# iND83213A register map
Vendor: Indiemicro; Series: Rugby; File version: 1.0
CPU: CM0 r0p1, selectable endian, no MPU, no FPU, 4 interrupt priority bits
Registers are 32-bit, read-write, no defined reset value unless marked. A register's access mark holds for its fields unless they carry their own. Offsets are from the block's base; [hi:lo] are bit positions; {n}, {i} and the like mark numbered series.

## SAR_CTRL — SAR ADC Interface registers
Base 0x50010600; register names take the prefix SAR_CTRL_
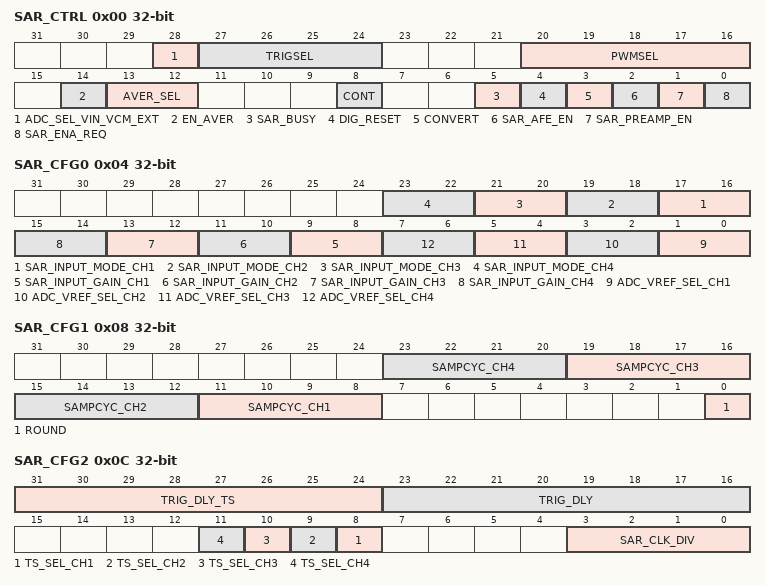
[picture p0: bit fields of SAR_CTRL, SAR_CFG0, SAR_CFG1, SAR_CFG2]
0x00 SAR_CTRL — SAR ADC Control
  [28] ADC_SEL_VIN_VCM_EXT — Select External Inputs to ADC. choose ADC input common voltage. 0: choose internal vin_vcm, equals to (vinp+vinn)/2; 1: choose external vin_vcm, for PN detect.
  [27:24] TRIGSEL — SAR Converion Trigger Selects. Selects the trigger condition of SAR ADC. Don't change the bits during an ADC conversion sequence is ongoing. 0x1: Triggered through writing 1 to conversion bit. 0x2: Triggered by the PWM posedge. 0x4: Triggered by the PWM negedge. 0x8: Triggered by PWM period.
  [20:16] PWMSEL — PWM Trigger Signal Selects. Selects the source PWM channel.
  [14] EN_AVER — Enable sample data average.
  [13:12] AVER_SEL — Select average numbers of adc sample data. 0x0: Average numbers of adc sample data: 4 0x1: Average numbers of adc sample data: 8 0x2: Average numbers of adc sample data: 16 0x3: Average numbers of adc sample data: 32
  [8] CONT — Continuous Conversion Enable. If this bit has been set before an ADC conversion sequence trigged by CONVERT bit, the sequence will be treated as a sequential conversion, rather than a single conversion, only value when auto_trg_en is disable.
  [5] SAR_BUSY ro — SAR ADC busy. When SAR ADC is running, the flag is set
  [4] DIG_RESET wo — SAR Digital Part Reset. Resets SAR digital parts. Autoclear: includes a synchronous reset signal which clears the register on the cycle following write.
  [3] CONVERT wo — ADC START Register. Set 1 to start a new adc conversion. NOTE: THAT BIT SHOULD NOT BE SET UNTIL ALL OTHER CONFIG BITS BE SETTED Autoclear: includes a synchronous reset signal which clears the register on the cycle following write.
  [2] SAR_AFE_EN — ADC AFE Enable. adc afe enable. If vinp, vinn and vin vcm all choose external, adc afe should be disabled: adc_adc_en=0, otherwise, adc afe must be enabled: adc_afe_en=1.
  [1] SAR_PREAMP_EN — adc pre-amp enable. 0:disable, 1:enable
  [0] SAR_ENA_REQ — SAR ADC Enable. Set to enable the SAR analog & digital part
0x04 SAR_CFG0 — SAR Configuration Register0
  [2n+15:2n+14] SAR_INPUT_MODE_CH{n} (n=1..4) — ADC AFE Input Modes for channel {n}. Select ADC AFE Input Modes. 0x0: All external. 0x1: VINP buffered, VINN external. 0x2: VINN buffered, VINP external. 0x3: Both VINP & VINN buffered.
  [2n+7:2n+6] SAR_INPUT_GAIN_CH{n} (n=1..4) — choose ADC input gain for channel {n}. 0x0: 14/32 0x1: 22/32 0x2: 31/32 0x3: 31/32
  [2n-1:2n-2] ADC_VREF_SEL_CH{n} (n=1..4) — adc vref select for channel {n}. 0x0: adc_vref = vbg when sar_ena_req=1 0x1: adc_vref = 2*vbg when sar_ena_req=1 0x2: adc_vref = VDD_3V3 when sar_ena_req=1 0x3: adc_vref = VDD_3V3 when sar_ena_req=1
0x08 SAR_CFG1 — SAR Configuration Register1
  [4n+7:4n+4] SAMPCYC_CH{n} (n=1..4) — Sample cycle for channel {n}. Set sampling time from 1 to 16 sar clock cycles. 0x0: 1 Cycle 0x1: 2 Cycle 0x2: 3 Cycle 0xf: 16 Cycle
  [0] ROUND — ADC round enable. Enable ADC round. 0x0: No round. 0x1: Negative code+1
0x0C SAR_CFG2 — SAR Configuration Register2
  [31:24] TRIG_DLY_TS — Trigger delay used for temp sensor sampling channel. Set trigger delay time from 1 to 256 sar clock cycles.
  [23:16] TRIG_DLY — Trigger delay used for non temp sensor sampling channel. Set trigger delay time from 1 to 256 sar clock cycles.
  [n+7] TS_SEL_CH{n} (n=1..4) — Temp sensor select for channel {n}. 1'b0: Temp sensor located in BUCK; 1'b1: Temp sensor located in LED. The value is only valid when Temp Sensor differential channel of CH{n} is selected.
  [3:0] SAR_CLK_DIV — SAR ADC reference clock div select. Select the divisor on the system clock after perscale. The sar adc clock = sysclk(16Mhz)/((CRGA.DIVSYSCLK+1)*(SAR_CLK_DIV+1)). The sar adc clock frequence must be no more than 4Mhz. The default sar adc clock: 1Mhz.
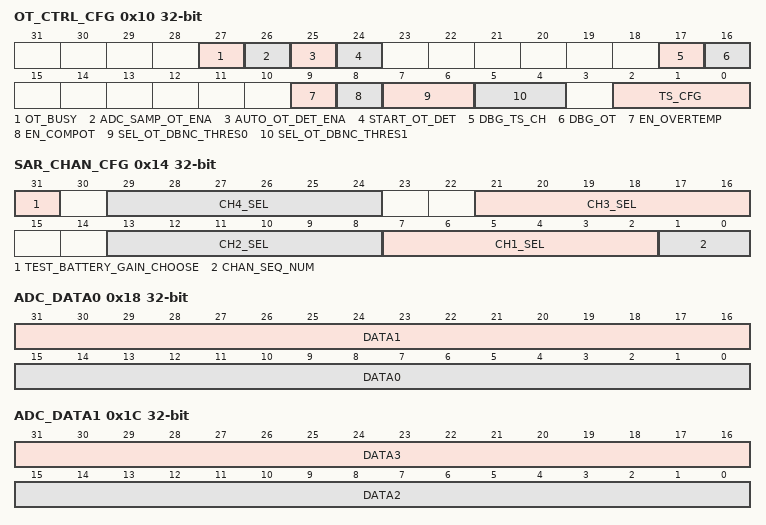
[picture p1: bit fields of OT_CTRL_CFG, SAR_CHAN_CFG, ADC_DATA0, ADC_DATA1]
0x10 OT_CTRL_CFG — Over-temperature detection control & Configuration
  [27] OT_BUSY ro — OT_BUSY. When over-temperature sensor is working, the bit is set to high.
  [26] ADC_SAMP_OT_ENA — ADC sampling temperature sensor enable.
  [25] AUTO_OT_DET_ENA — Auto OT detection enable.
  [24] START_OT_DET wo — Set 1 to launch a OT detect operation. It's a pulse signal and no need to clear it.
  [17] DBG_TS_CH — Select temperature sensor channel. Only used to test OT in debug mode.
  [16] DBG_OT — OT debug enable signal. Only used to test OT in debug mode.
  [9] EN_OVERTEMP — Enable over temperature sensor.
  [8] EN_COMPOT — Enable the comparator of over temperature function.
  [7:6] SEL_OT_DBNC_THRES0 — Select OT flag debounce threshold when a 1 turns into a 0. 0x0: 32us 0x1: 64us 0x2: 96us 0x3: 128us
  [5:4] SEL_OT_DBNC_THRES1 — Select OT flag debounce threshold when a 0 turns into a 1. 0x0: 32us 0x1: 64us 0x2: 96us 0x3: 128us
  [2:0] TS_CFG — Choose the OT level from 90~160 degree. 0x0: 160 degree 0x1: 150 degree 0x2: 140 degree 0x3: 130 degree 0x4: 120 degree 0x5: 110 degree 0x6: 100 degree 0x7: 90 degree
0x14 SAR_CHAN_CFG — SAR Channel Configuration
  [31] TEST_BATTERY_GAIN_CHOOSE — VBAT Gain Select. 0: gain=1/14, vbat max 30V/14=2.14v, under ADC vref=2.4v 1: gain=1/28, vbat max 30V/28=1.07v, under ADC vref=1.2v
  [29:24] CH4_SEL — Channel4 Selection. Refer to Channel1 Selects.
  [21:16] CH3_SEL — Channel3 Selection. Refer to Channel1 Selects.
  [13:8] CH2_SEL — Channel2 Selection. Refer to Channel1 Selects.
  [7:2] CH1_SEL — Channel1 Selection. Channel1 Selects. 0x0: adc_vinp=adc_refp, adc_vinn=adc_refp (all shot to adc_ref(2.4V) for adc channel offset K) 0x1: adc_vinp=adc_refp, adc_vinn=vref_gnd (for adc channel +gain error K) 0x2: adc_vinp=vref_gnd, adc_vinn=adc_refp (for adc channel -gain error K) 0x3: adc_vinp=GPIO6, adc_vinn=GPIO7,differential channel 0x4: Temp Sensor differential channel 0x5: adc_vinp=VDD_1V5, adc_vinn=vref_gnd 0x6: adc_vinp=VDD_3V3, adc_vinn=vref_gnd 0x7: adc_vinp=VDD_PRE5V(1/4), adc_vinn=vref_gnd 0x8: adc_vinp=VBAT ACCURATE (gain selected by TEST_BATTERY_GAIN_CHOOSE), adc_vinn=vref_gnd 0x9: adc_vinp=GPIO6, adc_vinn=vref_gnd. 0xa: adc_vinp=GPIO7, adc_vinn=vref_gnd. 0xb: adc_vinp=GPIO8, adc_vinn=vref_gnd. 0xc: adc_vinp=GPIO1, adc_vinn=vref_gnd. 0xd: adc_vinp=GPIO2, adc_vinn=vref_gnd. 0xe: adc_vinp=GPIO3, adc_vinn=vref_gnd. 0xf: adc_vinp=GPIO4, adc_vinn=vref_gnd. 0x10: adc_vinp=GPIO5, adc_vinn=vref_gnd. 0x11: adc_vinp=GPIO9, adc_vinn=vref_gnd. 0x12: adc_vinp=VBUCK 5V(1/4), adc_vinn=vref_gnd. 0x13: adc_vinp=VBUCK, adc_vinn=LED PN channel 0 . 0x14: adc_vinp=VBUCK, adc_vinn=LED PN channel 1 . 0x2a: adc_vinp=VBUCK, adc_vinn=LED PN channel 23.
  [1:0] CHAN_SEQ_NUM — Channel Sequence number. Select the sequence number of channels to be converted. 0x0: CH1 only 0x1: CH1->CH2 0x2: CH1->CH2->CH3 0x3: CH1->CH2->CH3->CH4
0x18 ADC_DATA0
  [31:16] DATA1 ro — Data1 of ADC conversion
  [15:0] DATA0 ro — Data0 of ADC conversion
0x1C ADC_DATA1
  [31:16] DATA3 ro — Data3 of ADC conversion
  [15:0] DATA2 ro — Data2 of ADC conversion
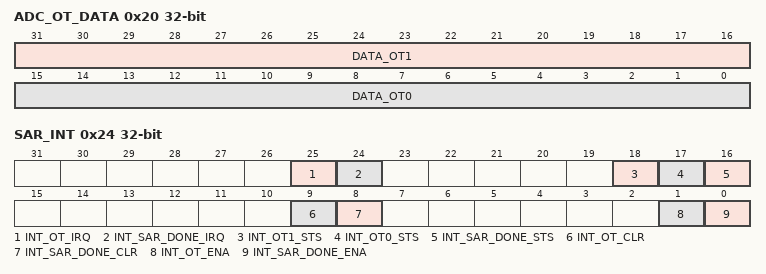
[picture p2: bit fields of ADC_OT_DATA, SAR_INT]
0x20 ADC_OT_DATA
  [31:16] DATA_OT1 ro — Data of ADC conversion for OT channel 1
  [15:0] DATA_OT0 ro — Data of ADC conversion for OT channel 0
0x24 SAR_INT — SAR Interrupts
  [25] INT_OT_IRQ ro — Over-temperature interrupt.
  [24] INT_SAR_DONE_IRQ ro — SAR convert done interrupt.
  [18] INT_OT1_STS ro — Over-temperature flag of OT channel 1. Set when an Over-temperature happens.
  [17] INT_OT0_STS ro — Over-temperature flag of OT channel 0. Set when an Over-temperature happens.
  [16] INT_SAR_DONE_STS ro — SAR convert done flag status. Set by the SAR when an conversion is done.
  [9] INT_OT_CLR wo — Over-temperature interrupt clear.
  [8] INT_SAR_DONE_CLR wo — SAR convert done interrupt clear.
  [1] INT_OT_ENA — Over-temperature interrupt enable.
  [0] INT_SAR_DONE_ENA — SAR convert done interrupt enable.
